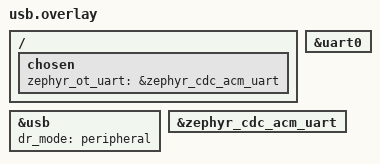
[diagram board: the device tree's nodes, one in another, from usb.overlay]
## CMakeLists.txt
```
cmake_minimum_required(VERSION 3.20.0)
find_package(Zephyr REQUIRED HINTS $ENV{ZEPHYR_BASE})
project(openthread_rcp)
```

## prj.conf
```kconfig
CONFIG_OPENTHREAD=y
CONFIG_OPENTHREAD_COPROCESSOR=y
CONFIG_OPENTHREAD_COPROCESSOR_RCP=y
CONFIG_NETWORKING=y
CONFIG_USB_DEVICE_STACK=y
CONFIG_USB_CDC_ACM=y
CONFIG_SERIAL=y
CONFIG_UART_INTERRUPT_DRIVEN=y
CONFIG_BOOTLOADER_MCUBOOT=y
CONFIG_BUILD_OUTPUT_UF2=y
```

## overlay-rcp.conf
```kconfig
CONFIG_USB_CDC_ACM=y
CONFIG_SERIAL=y
```

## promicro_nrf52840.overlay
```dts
/ {
    chosen {
        zephyr,ot-uart = &cdc_acm_uart0;
    };
};

&zephyr_udc0 {
    status = "okay";
    cdc_acm_uart0: cdc_acm_uart0 {
        compatible = "zephyr,cdc-acm-uart";
    };
};
```

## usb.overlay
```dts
&uart0 {
    status = "okay";
};

&usb {
    status = "okay";
    dr_mode = "peripheral";
};

&zephyr_cdc_acm_uart {
    status = "okay";
};

/ {
    chosen {
        zephyr_ot_uart = &zephyr_cdc_acm_uart;
    };
};
```

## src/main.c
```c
#include <zephyr/kernel.h>

int main(void)
{
    /* OpenThread coprocessor otomatik başlar */
    return 0;
}
```
